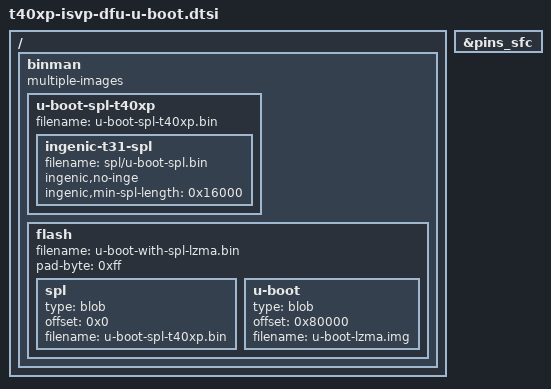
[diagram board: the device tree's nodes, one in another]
// SPDX-License-Identifier: GPL-2.0+
/*
 * Binman image description for the Ingenic ISVP-T40XP DFU loader.
 *
 * The USB-boot path uploads spl/u-boot-spl.bin + u-boot.bin directly
 * via the mask ROM (tools/t31-usbboot.py); the binman flash image
 * here is not used. Kept consistent with the SFC-NAND layout
 * (headered SPL at 0, LZMA U-Boot at 0x80000) so a stray 'make'
 * still produces a sensible flash image.
 */

#include "t40-isvp-dfu-uboot-common.dtsi"

/ {
	binman: binman {
		multiple-images;
	};
};

&binman {
	u-boot-spl-t40xp {
		filename = "u-boot-spl-t40xp.bin";

		ingenic-t31-spl {
			filename = "spl/u-boot-spl.bin";
			ingenic,no-inge;
			ingenic,min-spl-length = <0x16000>;
		};
	};

	flash {
		filename = "u-boot-with-spl-lzma.bin";
		pad-byte = <0xff>;

		spl {
			type = "blob";
			offset = <0x0>;
			filename = "u-boot-spl-t40xp.bin";
		};

		u-boot {
			type = "blob";
			offset = <0x80000>;
			filename = "u-boot-lzma.img";
		};
	};
};

/* NAND SPL (mach-xburst/t40/sfc_nand.c) reads the flash in SPL, so the
 * SFC pins must be configured there. Relocated from t40xp-isvp-dfu.dts.
 */
&pins_sfc {
	bootph-all;
};
